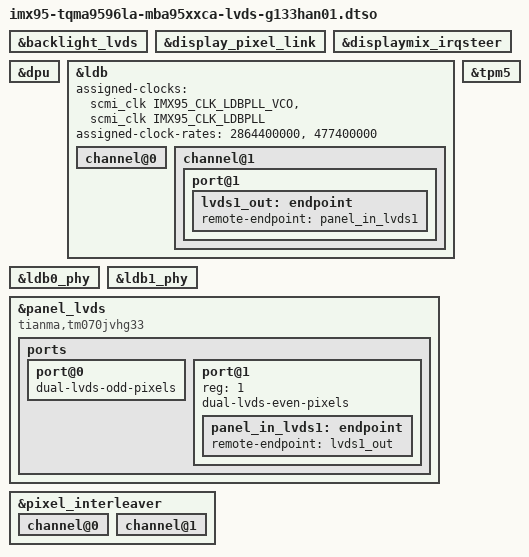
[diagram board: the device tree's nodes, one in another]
// SPDX-License-Identifier: (GPL-2.0-or-later OR MIT)
/*
 * Copyright (c) 2026 TQ-Systems GmbH <linux@ew.tq-group.com>,
 * D-82229 Seefeld, Germany.
 * Author: Alexander Stein
 * Author: Markus Niebel
 */

/dts-v1/;
/plugin/;

#include "imx95-clock.h"

&backlight_lvds {
	status = "okay";
};

&display_pixel_link {
	status = "okay";
};

&displaymix_irqsteer {
	status = "okay";
};

&dpu {
	status = "okay";
};

&ldb {
	/* IMX95_CLK_LDBPLL: 7x display pixel clock */
	/* IMX95_CLK_LDBPLL_VCO: 6x IMX95_CLK_LDBPLL */
	assigned-clocks = <&scmi_clk IMX95_CLK_LDBPLL_VCO>,
			  <&scmi_clk IMX95_CLK_LDBPLL>;
	assigned-clock-rates = <2864400000>, <477400000>;
	status = "okay";

	channel@0 {
		status = "okay";
	};

	channel@1 {
		status = "okay";

		port@1 {
			lvds1_out: endpoint {
				remote-endpoint = <&panel_in_lvds1>;
			};
		};
	};
};

&ldb0_phy {
	status = "okay";
};

&ldb1_phy {
	status = "okay";
};

&panel_lvds {
	compatible = "tianma,tm070jvhg33";
	status = "okay";

	ports {
		#address-cells = <1>;
		#size-cells = <0>;

		port@0 {
			dual-lvds-odd-pixels;
		};

		port@1 {
			reg = <1>;
			dual-lvds-even-pixels;

			panel_in_lvds1: endpoint {
				remote-endpoint = <&lvds1_out>;
			};
		};
	};
};

&pixel_interleaver {
	status = "okay";

	channel@0 {
		status = "okay";
	};

	channel@1 {
		status = "okay";
	};
};

&tpm5 {
	status = "okay";
};
